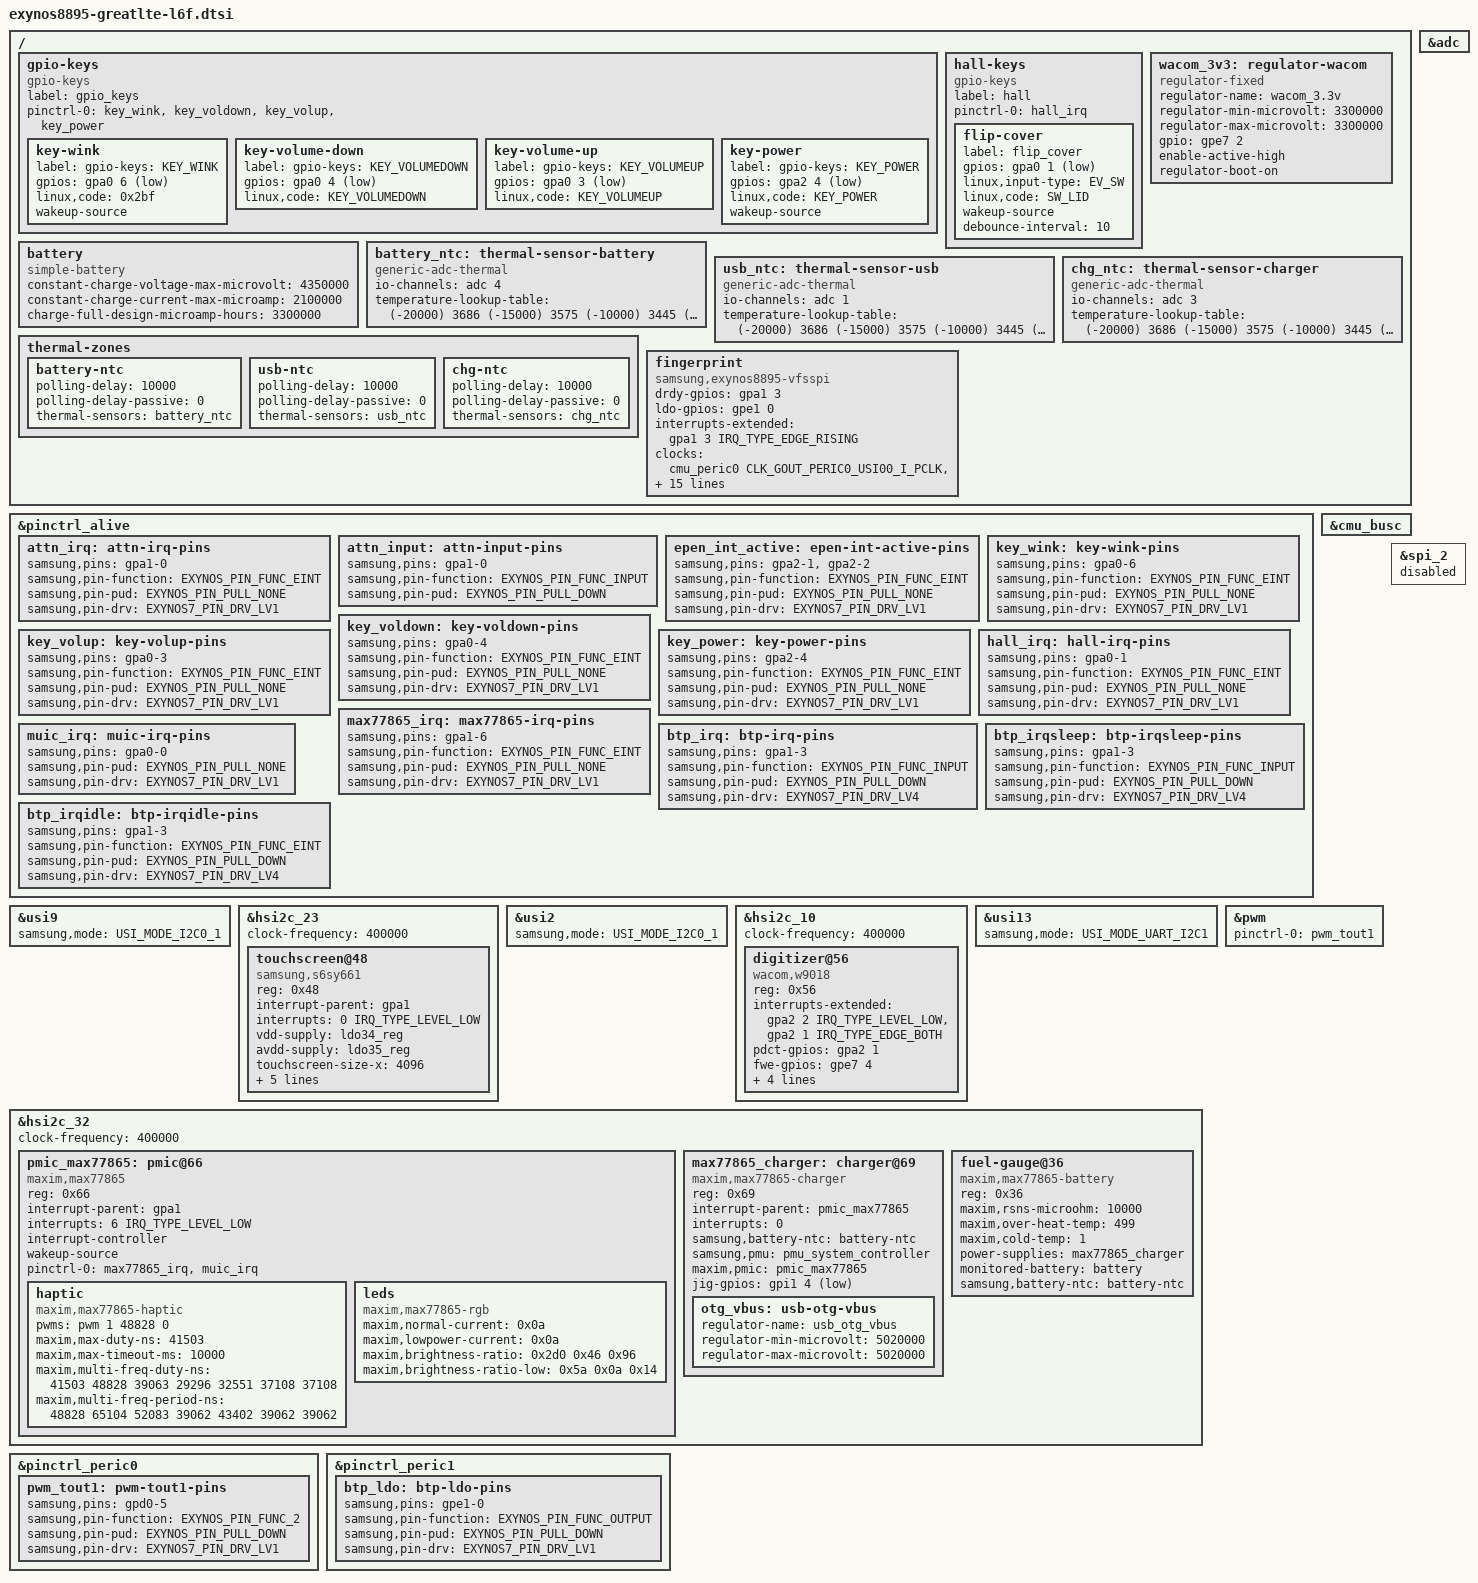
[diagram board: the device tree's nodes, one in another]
// SPDX-License-Identifier: GPL-2.0 OR BSD-3-Clause
/*
 * Samsung Galaxy Note 8 (greatlte, SM-N950N) board DT, part "l6f":
 * L6F power/input/misc: charger, fuel gauge, touch, S Pen, keys, fingerprint (L6F 4).
 *
 * Included at the end of exynos8895-greatlte.dts, after L0's nodes, in the merge
 * order of FULL_IMAGE_PLAN.md 2.2. Owner: WP-6F; no other work package edits this
 * file (plan 2.3 rule D1). A node that two parts both configure (&usi9, &usi10)
 * is written identically in both files: dtc lets the later file win on a differing
 * value, which gl-verify V-DUP reports as an error. L0's reserved-memory stays in
 * the .dts; carveout additions and flag changes are &label edits here (plan X-8).
 */
&pinctrl_alive {
	attn_irq: attn-irq-pins {			/* FDT:266-273 (0x66), touch on_state */
		samsung,pins = "gpa1-0";
		samsung,pin-function = <EXYNOS_PIN_FUNC_EINT>;
		samsung,pin-pud = <EXYNOS_PIN_PULL_NONE>;
		samsung,pin-drv = <EXYNOS7_PIN_DRV_LV1>;
	};
	attn_input: attn-input-pins {			/* FDT:275-281 (0x67), touch off_state; stock sets no drv */
		samsung,pins = "gpa1-0";
		samsung,pin-function = <EXYNOS_PIN_FUNC_INPUT>;
		samsung,pin-pud = <EXYNOS_PIN_PULL_DOWN>;	/* pud 1 */
	};
	/* greatlte L6F slice pen (L6F 4.2) */
	epen_int_active: epen-int-active-pins {		/* FDT:354-361 (0x4e) */
		samsung,pins = "gpa2-1", "gpa2-2";
		samsung,pin-function = <EXYNOS_PIN_FUNC_EINT>;
		samsung,pin-pud = <EXYNOS_PIN_PULL_NONE>;
		samsung,pin-drv = <EXYNOS7_PIN_DRV_LV1>;
	};
};

&usi9 {
	samsung,mode = <USI_MODE_I2C0_1>;		/* stock usi@1082101C "hsi2c0_hsi2c1" FDT:5049-5053 */
	status = "okay";
};

&hsi2c_23 {						/* stock hsi2c@108E0000 FDT:5666-5683 (SPI 0x19a = 410) */
	clock-frequency = <400000>;		/* no clock-frequency in FDT:5666-5683 -> stock 400 kHz default (as 4.3) */
	status = "okay";

	touchscreen@48 {
		compatible = "samsung,s6sy661";		/* new s6sy761 variant (5.12); stock "sec,sec_ts" FDT:5685 */
		reg = <0x48>;				/* FDT:5686 */
		interrupt-parent = <&gpa1>;
		interrupts = <0 IRQ_TYPE_LEVEL_LOW>;	/* FDT:5692 sec,irq_gpio = <&gpa1 0 0>; FDT:5693 irq_type 0x2008 =
							   IRQF_ONESHOT | IRQF_TRIGGER_LOW */
		vdd-supply = <&ldo34_reg>;		/* FDT:5696 "tsp_io" (L2_power.md:646-651) */
		avdd-supply = <&ldo35_reg>;		/* FDT:5697 "tsp_avdd" (L2_power.md:652-657) */
		touchscreen-size-x = <4096>;		/* FDT:5694 sec,max_coords 0xfff = size - 1; chip value - 1 in stock (sec_ts.c:1922-1926) */
		touchscreen-size-y = <4096>;
		pinctrl-names = "default", "sleep";	/* FDT:5687 "on_state", "off_state" */
		pinctrl-0 = <&attn_irq>;		/* FDT:5688 0x66 */
		pinctrl-1 = <&attn_input>;		/* FDT:5689 0x67 */
		samsung,sponge-model = "N950";		/* stock sec,project_name = "GREAT", "N950" (S:arch/arm64/boot/dts/exynos/
							   exynos8895-greatlte_common.dtsi:3256; model_name = entry 1, sec_ts.c:1801-1802)
							   and pressure-sensor = "Y" (:3245): the under-display pressure home key */
		panel = <&panel>;			/* run 7: DRM panel follower, 5.12 item 13 (closes O-TS3); label from
							   L5 (REQ-L5-1); delete to keep touch powered while awake */
	};
};

/* Keys and hall (L6F slice A) */
#include <dt-bindings/input/input.h>

&pinctrl_alive {
	key_wink: key-wink-pins {			/* FDT:283-290 (phandle 0x145) */
		samsung,pins = "gpa0-6";
		samsung,pin-function = <EXYNOS_PIN_FUNC_EINT>;	/* 0x0f */
		samsung,pin-pud = <EXYNOS_PIN_PULL_NONE>;
		samsung,pin-drv = <EXYNOS7_PIN_DRV_LV1>;
	};
	key_voldown: key-voldown-pins {			/* FDT:292-299 (0x146) */
		samsung,pins = "gpa0-4";
		samsung,pin-function = <EXYNOS_PIN_FUNC_EINT>;
		samsung,pin-pud = <EXYNOS_PIN_PULL_NONE>;
		samsung,pin-drv = <EXYNOS7_PIN_DRV_LV1>;
	};
	key_volup: key-volup-pins {			/* FDT:301-308 (0x147) */
		samsung,pins = "gpa0-3";
		samsung,pin-function = <EXYNOS_PIN_FUNC_EINT>;
		samsung,pin-pud = <EXYNOS_PIN_PULL_NONE>;
		samsung,pin-drv = <EXYNOS7_PIN_DRV_LV1>;
	};
	key_power: key-power-pins {			/* FDT:310-317 (0x148) */
		samsung,pins = "gpa2-4";
		samsung,pin-function = <EXYNOS_PIN_FUNC_EINT>;
		samsung,pin-pud = <EXYNOS_PIN_PULL_NONE>;
		samsung,pin-drv = <EXYNOS7_PIN_DRV_LV1>;
	};
	hall_irq: hall-irq-pins {			/* FDT:248-255 (0x142) */
		samsung,pins = "gpa0-1";
		samsung,pin-function = <EXYNOS_PIN_FUNC_EINT>;
		samsung,pin-pud = <EXYNOS_PIN_PULL_NONE>;
		samsung,pin-drv = <EXYNOS7_PIN_DRV_LV1>;
	};
};

/ {
	gpio-keys {
		compatible = "gpio-keys";			/* FDT:11246 */
		label = "gpio_keys";				/* input name = stock "gpio_keys" (recon/input/input.txt:57);
								   A:drivers/input/keyboard/gpio_keys.c:778, :879 */
		pinctrl-names = "default";
		pinctrl-0 = <&key_wink &key_voldown &key_volup &key_power>;	/* FDT:11250 <0x145..0x148> */

		key-wink {
			label = "gpio-keys: KEY_WINK";		/* FDT:11253 */
			gpios = <&gpa0 6 GPIO_ACTIVE_LOW>;	/* FDT:11257 <0x90 6 0xf> (bit 0 = active low) */
			linux,code = <0x2bf>;			/* FDT:11256; Samsung KEY_WINK S:include/uapi/linux/input-event-codes.h:341,
								   inside 6.18 KEY_MAX 0x2ff A:include/uapi/linux/input-event-codes.h:837 */
			wakeup-source;				/* FDT:11258 gpio-key,wakeup */
		};
		key-volume-down {
			label = "gpio-keys: KEY_VOLUMEDOWN";	/* FDT:11262 */
			gpios = <&gpa0 4 GPIO_ACTIVE_LOW>;	/* FDT:11266 */
			linux,code = <KEY_VOLUMEDOWN>;		/* 0x72 FDT:11265 */
		};
		key-volume-up {
			label = "gpio-keys: KEY_VOLUMEUP";	/* FDT:11270 */
			gpios = <&gpa0 3 GPIO_ACTIVE_LOW>;	/* FDT:11274 */
			linux,code = <KEY_VOLUMEUP>;		/* 0x73 FDT:11273 */
		};
		key-power {
			label = "gpio-keys: KEY_POWER";		/* FDT:11278 */
			gpios = <&gpa2 4 GPIO_ACTIVE_LOW>;	/* FDT:11282 <0x4f 4 0xf> (0x4f = gpa2) */
			linux,code = <KEY_POWER>;		/* 0x74 FDT:11281 */
			wakeup-source;				/* FDT:11283 */
		};
	};

	hall-keys {
		compatible = "gpio-keys";
		label = "hall";					/* stock input name S:drivers/input/hall.c:252 */
		pinctrl-names = "default";
		pinctrl-0 = <&hall_irq>;			/* FDT:11206 0x142 */

		flip-cover {
			label = "flip_cover";
			gpios = <&gpa0 1 GPIO_ACTIVE_LOW>;	/* FDT:11207 hall,gpio_flip_cover = <&gpa0 1 0>; level 1 = open
								   (S:drivers/input/hall.c:98-104), so active-low = closed */
			linux,input-type = <EV_SW>;
			linux,code = <SW_LID>;			/* 0x00 A:include/uapi/linux/input-event-codes.h:934; stock SW_FLIP 0x15 > SW_MAX 0x11 (:954) */
			wakeup-source;
			debounce-interval = <10>;		/* stock 10 ms on open, 0 on close: S:drivers/input/hall.c:115-121 */
		};
	};
};

/* greatlte L6F slice pen (L6F 4.9) */
/ {
	wacom_3v3: regulator-wacom {
		compatible = "regulator-fixed";			/* FDT:11963-11971 wacom_ldo_en */
		regulator-name = "wacom_3.3v";			/* FDT:11965 */
		regulator-min-microvolt = <3300000>;		/* FDT:11966 0x325aa0 */
		regulator-max-microvolt = <3300000>;
		gpio = <&gpe7 2 GPIO_ACTIVE_HIGH>;		/* FDT:11968 <0x51 2 0> (0x51 = gpe7) */
		enable-active-high;				/* FDT:11969 */
		regulator-boot-on;				/* FDT:11970 */
	};
};

&usi2 {
	samsung,mode = <USI_MODE_I2C0_1>;		/* stock usi@10421008 "hsi2c0_hsi2c1" FDT:5001-5005 */
	status = "okay";
};

&hsi2c_10 {						/* stock hsi2c@10490000 FDT:5350-5366 (SPI 0x175 = 373) */
	clock-frequency = <400000>;		/* no clock-frequency in FDT:5350-5366 -> stock 400 kHz default (as 4.3) */
	status = "okay";

	digitizer@56 {
		compatible = "wacom,w9018";		/* new driver (5.13); stock "wacom,w90xx" FDT:5369 */
		reg = <0x56>;				/* FDT:5370 */
		interrupts-extended = <&gpa2 2 IRQ_TYPE_LEVEL_LOW>,	/* data: FDT:5376 wacom,irq-gpio = <&gpa2 2 1>; FDT:5379 irq_type 0x08 =
								   IRQF_TRIGGER_LOW. Stock "interrupts = <3 0 0>" (FDT:5373) is unused: stock takes
								   the IRQ from the gpio (S:drivers/input/wacom/wacom_i2c.c:2848) */
				      <&gpa2 1 IRQ_TYPE_EDGE_BOTH>;	/* pdct: S:.../wacom_i2c.c:2849, :2961-2965 FALLING|RISING */
		interrupt-names = "data", "pdct";
		pdct-gpios = <&gpa2 1 GPIO_ACTIVE_HIGH>;	/* FDT:5377 wacom,pdct-gpio = <&gpa2 1 1>; stock ignores the flag and uses the raw
							   level, 1 = pen in the garage (S:drivers/input/wacom/wacom_i2c.c:1736-1750), so
							   active-high makes gpiod_get_value() = "inserted" (SW_PEN_INSERTED semantics) */
		fwe-gpios = <&gpe7 4 GPIO_ACTIVE_HIGH>;	/* FDT:5378 */
		vddo-supply = <&wacom_3v3>;		/* FDT:5375 */
		wacom,xy-switch;			/* FDT:5388 wacom,invert = <1 0 1>: x_invert 1, y_invert 0, xy_switch 1 */
		wacom,x-invert;
		pinctrl-names = "default";
		pinctrl-0 = <&epen_int_active>;		/* FDT:5372 0x4e */
	};
};

/* ---- slice pwr: MAX77865 MFD, charger, fuel gauge, battery, AP ADC + NTC (L6F 4.2-4.4) ---- */
#include <dt-bindings/gpio/gpio.h>

&pinctrl_alive {
	max77865_irq: max77865-irq-pins {		/* FDT:467-474 (0x8d) */
		samsung,pins = "gpa1-6";
		samsung,pin-function = <EXYNOS_PIN_FUNC_EINT>;	/* 0x0f */
		samsung,pin-pud = <EXYNOS_PIN_PULL_NONE>;
		samsung,pin-drv = <EXYNOS7_PIN_DRV_LV1>;
	};
	muic_irq: muic-irq-pins {			/* FDT:476-482 (0x8e): stock sets no function */
		samsung,pins = "gpa0-0";
		samsung,pin-pud = <EXYNOS_PIN_PULL_NONE>;
		samsung,pin-drv = <EXYNOS7_PIN_DRV_LV1>;
	};
};

/* the AP ADC's clock provider (L1b CMU_BUSC, REQ-L1-6; enabled with the ADC, commit d98884fd8) */
&cmu_busc {
	status = "okay";
};

&adc {
	status = "okay";
};

/* identical to exynos8895-greatlte-l3.dtsi (plan 2.3 D1) */
&usi13 {
	samsung,mode = <USI_MODE_UART_I2C1>;	/* stock usi@1082102C usi_mode = "uart_hsi2c1" FDT:5077-5081 */
	status = "okay";
};

&hsi2c_32 {					/* stock hsi2c@10970000 FDT:6149-6163 (SPI 0x1ab = 427) */
	#address-cells = <1>;			/* FDT:6154 (the ACK node has none) */
	#size-cells = <0>;			/* FDT:6155 */
	clock-frequency = <400000>;		/* FDT:6149-6163 has no clock-frequency -> stock default
						   HSI2C_FS_TX_CLOCK 400000 (S:drivers/i2c/busses/i2c-exynos5.c:212,1572-1574) */
	status = "okay";

	pmic_max77865: pmic@66 {
		compatible = "maxim,max77865";			/* FDT:6166 */
		reg = <0x66>;					/* FDT:6169 */
		interrupt-parent = <&gpa1>;
		interrupts = <6 IRQ_TYPE_LEVEL_LOW>;		/* FDT:6170 max77865,irq-gpio = <&gpa1 6 1>;
								   S:drivers/mfd/max77865-irq.c:286-287 IRQF_TRIGGER_LOW */
		interrupt-controller;				/* INTSRC demux (L6F 5.2) */
		#interrupt-cells = <1>;
		wakeup-source;					/* FDT:6173 max77865,wakeup */
		pinctrl-names = "default";
		pinctrl-0 = <&max77865_irq &muic_irq>;		/* FDT:6168 <0x8d 0x8e 0x8f>; 0x8f (pwm-tout1) is the PWM's */

		/* slice hlp: haptic and LED child nodes (L6F 4.3) */
		haptic {
			compatible = "maxim,max77865-haptic";
			pwms = <&pwm 1 48828 0>;		/* FDT:12440 haptic,pwm_id = <1>; FDT:12438 period[0] 0xbebc;
								   index 0 = default S:drivers/motor/max77865_haptic.c:726 */
			maxim,max-duty-ns = <41503>;		/* FDT:12437 haptic,duty[0] 0xa21f (5.7) */
			maxim,max-timeout-ms = <10000>;		/* FDT:12435 haptic,max_timeout = <0x2710> */
			/*
			 * Samsung's haptic,duty and haptic,period (exynos8895-greatlte_motor.dtsi):
			 * alert, low, mid, high, 0, home key press, home key release
			 */
			maxim,multi-freq-duty-ns = <41503 48828 39063 29296 32551 37108 37108>;
			maxim,multi-freq-period-ns = <48828 65104 52083 39062 43402 39062 39062>;
		};

		leds {
			compatible = "maxim,max77865-rgb";
			/* FDT:12444-12511: every window-colour variant (_uu _bk _wh _gd _sv _gr _bl _pg) carries the same values
			 * (python check of the rgb node), so no lcdtype lookup is needed */
			maxim,normal-current = <0x0a>;		/* normal_powermode_current_uu FDT:12447 */
			maxim,lowpower-current = <0x0a>;	/* low_powermode_current_uu FDT:12448 */
			maxim,brightness-ratio = <0x2d0 0x46 0x96>;	/* br_ratio_r/g/b_uu FDT:12449-12451 */
			maxim,brightness-ratio-low = <0x5a 0x0a 0x14>;	/* br_ratio_r/g/b_low_uu FDT:12452-12454 */
		};
	};

	max77865_charger: charger@69 {			/* 0xD2 >> 1: S:drivers/mfd/max77865.c:46 */
		compatible = "maxim,max77865-charger";
		reg = <0x69>;
		interrupt-parent = <&pmic_max77865>;
		interrupts = <0>;			/* INTSRC bit 0 CHG: S:include/linux/mfd/max77865-private.h:30 */
		samsung,battery-ntc = "battery-ntc";	/* thermal zone below (L6F 4.4) */
		samsung,pmu = <&pmu_system_controller>;	/* INFORM2 write on power-off with charger (L6F 5.3.7) */
		maxim,pmic = <&pmic_max77865>;		/* core regmap for MAINCTRL1 (L6F 5.3.2 step 12) */
		jig-gpios = <&gpi1 4 GPIO_ACTIVE_LOW>;	/* FDT:12332-12333 fuelgauge,jig_gpio = <&gpi1 4 0> + jig_low_active
						   (0x8a = gpi1, FDT:705-711); requested GPIOD_ASIS (V4-16) */
		/*
		 * samsung,charge-control; (L6F 4.3, 5.3.2) is left out for now: monitor-only until
		 * the readings are checked on the phone and the charge-control path is reviewed.
		 */

		otg_vbus: usb-otg-vbus {		/* stock "otg" supply as a regulator (L6F 5.3.8) */
			regulator-name = "usb_otg_vbus";
			regulator-min-microvolt = <5020000>;	/* CNFG_11 := 0x16 "Update CHG_CNFG_11 to 0x16(5.020V)"
								   S:drivers/battery_v2/max77865_charger.c:656-658 */
			regulator-max-microvolt = <5020000>;
			/* no consumer in this image (L3 peripheral-only); host-role owner: O-J21 */
		};
	};

	fuel-gauge@36 {					/* 0x6C >> 1: S:drivers/mfd/max77865.c:47 */
		compatible = "maxim,max77865-battery";
		reg = <0x36>;
		/* no interrupts: SALRT_Th := 0xff00 path (A:drivers/power/supply/max17042_battery.c:1117-1119) */
		maxim,rsns-microohm = <10000>;		/* FDT:12351 fuelgauge,fg_resistor = <1>;
							   S:drivers/battery_v2/max77865_fuelgauge.c:535-541 10 mOhm */
		maxim,over-heat-temp = <499>;		/* FDT:12225 temp_high_threshold_normal 0x1f4 (50.0 degC); stock
							   T >= 500 (S:drivers/battery_v2/sec_battery.c:1972), max17042
							   temp > temp_max (A:drivers/power/supply/max17042_battery.c:218) */
		maxim,cold-temp = <1>;			/* FDT:12227 temp_low_threshold_normal 0x00; stock T <= 0 (:2014),
							   max17042 temp < temp_min (:213) */
		/* no maxim,over-volt / maxim,dead-volt: stock has no battery-voltage health limit,
		 * battery,ovp_uvlo_check_type 3 = charger polling (FDT:12215, L6F 4.3, O-J15) */
		power-supplies = <&max77865_charger>;	/* STATUS needs a supplier (A:.../max17042_battery.c:119-127) */
		monitored-battery = <&battery>;
		samsung,battery-ntc = "battery-ntc";	/* host temperature source (L6F 5.4) */
	};
};

/ {
	battery: battery {
		compatible = "simple-battery";
		constant-charge-voltage-max-microvolt = <4350000>;	/* FDT:12281-12282 0xa9ec = 43500 / conv 0x0a */
		constant-charge-current-max-microamp = <2100000>;	/* FDT:12361 default_charging_current = <0x834> */
		charge-full-design-microamp-hours = <3300000>;		/* FDT:12312 battery,battery_full_capacity = <0xce4> */
	};

	/*
	 * Battery NTC = ADC 4, USB-connector NTC = ADC 1, charger NTC = ADC 3
	 * (FDT:12323-12324 "adc-temp" <0x141 0x04>, "adc-usb-temp" <0x141 0x01>,
	 * "adc-chg-temp" <0x141 0x03>). Tables: FDT:12188-12189 battery,temp_table_adc /
	 * temp_table_data as <milli-degC code> pairs, code falling, as
	 * gadc_thermal_adc_to_temp() needs (A:drivers/thermal/thermal-generic-adc.c:27-56);
	 * the usb and chg tables FDT:12190-12193 are equal to it.
	 */
	battery_ntc: thermal-sensor-battery {
		compatible = "generic-adc-thermal";		/* A:drivers/thermal/thermal-generic-adc.c:212-214 */
		#thermal-sensor-cells = <0>;
		io-channels = <&adc 4>;
		io-channel-names = "sensor-channel";
		temperature-lookup-table = <
			(-20000) 3686	(-15000) 3575	(-10000) 3445	(-5000) 3293
			0 3122		5000 2932	10000 2726	15000 2512
			20000 2291	25000 2048	30000 1811	35000 1586
			40000 1378	45000 1189	50000 1021	55000 887
			60000 769	65000 655	70000 558	75000 474
			80000 404	85000 345	90000 294 >;
	};

	usb_ntc: thermal-sensor-usb {
		compatible = "generic-adc-thermal";
		#thermal-sensor-cells = <0>;
		io-channels = <&adc 1>;
		io-channel-names = "sensor-channel";
		temperature-lookup-table = <
			(-20000) 3686	(-15000) 3575	(-10000) 3445	(-5000) 3293
			0 3122		5000 2932	10000 2726	15000 2512
			20000 2291	25000 2048	30000 1811	35000 1586
			40000 1378	45000 1189	50000 1021	55000 887
			60000 769	65000 655	70000 558	75000 474
			80000 404	85000 345	90000 294 >;
	};

	chg_ntc: thermal-sensor-charger {
		compatible = "generic-adc-thermal";
		#thermal-sensor-cells = <0>;
		io-channels = <&adc 3>;
		io-channel-names = "sensor-channel";
		temperature-lookup-table = <
			(-20000) 3686	(-15000) 3575	(-10000) 3445	(-5000) 3293
			0 3122		5000 2932	10000 2726	15000 2512
			20000 2291	25000 2048	30000 1811	35000 1586
			40000 1378	45000 1189	50000 1021	55000 887
			60000 769	65000 655	70000 558	75000 474
			80000 404	85000 345	90000 294 >;
	};

	thermal-zones {
		battery-ntc {
			polling-delay = <10000>;	/* 10 s = FDT:12187 battery,polling_time[0] (BASIC) 0x0a */
			polling-delay-passive = <0>;
			thermal-sensors = <&battery_ntc>;
			/* no trips: allowed (A:drivers/thermal/thermal_of.c:387-395) */
		};

		usb-ntc {
			polling-delay = <10000>;	/* same cadence as battery-ntc */
			polling-delay-passive = <0>;
			thermal-sensors = <&usb_ntc>;
		};

		chg-ntc {
			polling-delay = <10000>;
			polling-delay-passive = <0>;
			thermal-sensors = <&chg_ntc>;
		};
	};
};

/* slice hlp: PWM pin and board PWM (L6F 4.2, 4.5) */
&pinctrl_peric0 {
	pwm_tout1: pwm-tout1-pins {			/* FDT:1529-1535 (0x8f) */
		samsung,pins = "gpd0-5";
		samsung,pin-function = <EXYNOS_PIN_FUNC_2>;
		samsung,pin-pud = <EXYNOS_PIN_PULL_DOWN>;	/* pud 1 */
		samsung,pin-drv = <EXYNOS7_PIN_DRV_LV1>;
	};
};

&pwm {
	pinctrl-names = "default";
	pinctrl-0 = <&pwm_tout1>;			/* stock applied through the MFD node (FDT:6168 third entry 0x8f) */
	status = "okay";
};

/* slice fp: fingerprint sensor, non-secure side (L6F 4.2, 4.7) */
&pinctrl_alive {
	btp_irq: btp-irq-pins {				/* FDT:424-431 (0x9f) */
		samsung,pins = "gpa1-3";
		samsung,pin-function = <EXYNOS_PIN_FUNC_INPUT>;
		samsung,pin-pud = <EXYNOS_PIN_PULL_DOWN>;	/* pud 1 */
		samsung,pin-drv = <EXYNOS7_PIN_DRV_LV4>;	/* 3 */
	};
	btp_irqsleep: btp-irqsleep-pins {		/* FDT:433-440 (0xa1) */
		samsung,pins = "gpa1-3";
		samsung,pin-function = <EXYNOS_PIN_FUNC_INPUT>;
		samsung,pin-pud = <EXYNOS_PIN_PULL_DOWN>;
		samsung,pin-drv = <EXYNOS7_PIN_DRV_LV4>;
	};
	btp_irqidle: btp-irqidle-pins {			/* FDT:442-449 (0xa2) */
		samsung,pins = "gpa1-3";
		samsung,pin-function = <EXYNOS_PIN_FUNC_EINT>;
		samsung,pin-pud = <EXYNOS_PIN_PULL_DOWN>;
		samsung,pin-drv = <EXYNOS7_PIN_DRV_LV4>;
	};
};

&pinctrl_peric1 {
	btp_ldo: btp-ldo-pins {				/* FDT:3860-3867 (0xa0) */
		samsung,pins = "gpe1-0";
		samsung,pin-function = <EXYNOS_PIN_FUNC_OUTPUT>;
		samsung,pin-pud = <EXYNOS_PIN_PULL_DOWN>;
		samsung,pin-drv = <EXYNOS7_PIN_DRV_LV1>;
	};
};

&spi_2 { status = "disabled"; };	/* FDT:6282 secure-mode: TEE owns the controller; usi0 never programmed (REQ-L1-3b, plan X-16) */

/ {
	fingerprint {
		compatible = "samsung,exynos8895-vfsspi";	/* platform device, not an SPI child (L6F 5.10) */
		drdy-gpios = <&gpa1 3 GPIO_ACTIVE_HIGH>;	/* FDT:6294 vfsspi-drdyPin = <&gpa1 3 0> (0x69 = gpa1) */
		ldo-gpios = <&gpe1 0 GPIO_ACTIVE_HIGH>;		/* FDT:6295 vfsspi-ldoPin = <&gpe1 0 0> (0x5b = gpe1) */
		interrupts-extended = <&gpa1 3 IRQ_TYPE_EDGE_RISING>;	/* DRDY: S:drivers/fingerprint/vfs8xxx.h:26 DRDY_IRQ_FLAG IRQF_TRIGGER_RISING */
		clocks = <&cmu_peric0 CLK_GOUT_PERIC0_USI00_I_PCLK>,	/* stock "fp-spi-pclk" GATE_USI00 S:drivers/clk/samsung/clk-exynos8895.c:372 */
			 <&cmu_peric0 CLK_GOUT_PERIC0_USI00_I_SCLK_USI>,
			 <&cmu_top CLK_DOUT_CMU_PERIC0_USI00>,		/* stock "fp-spi-sclk" (:542), rate set 2 x 13 MHz (5.10) */
			 <&cmu_peric0 CLK_GOUT_PERIC0_USI00_QCH>;	/* REQ-L1-10: the Q-channel CLOCK_REQ gate stock drives for
									   GATE_USI00 (VCLK_QCH_DIS) */
		clock-names = "pclk", "sclk_gate", "sclk", "qch";
		/* stock fp-spi-sclk vclk at 26000 kHz = TOP mux USI00 := OSCCLK (0), div := /1 (V4-11:
		 * S:drivers/soc/samsung/cal-if/exynos8895/cmucal-vclk.c:2586-2593, cmucal-vclklut.c:158-160);
		 * ACK muxes never reparent on set_rate (A:drivers/clk/samsung/clk.h:144-145), so select the parent here */
		assigned-clocks = <&cmu_top CLK_MOUT_CMU_PERIC0_USI00>, <&cmu_top CLK_DOUT_CMU_PERIC0_USI00>;
		assigned-clock-parents = <&oscclk>, <0>;
		assigned-clock-rates = <0>, <26000000>;
		spi-max-frequency = <13000000>;			/* FDT:6287 0xc65d40; S:drivers/fingerprint/vfs8xxx.h:20 */
		samsung,orient = <1>;				/* FDT:6296 vfsspi-orient */
		samsung,detect-mode = <1>;			/* FDT:6297 vfsspi-wog (DETECT_ADM, S:drivers/fingerprint/fingerprint.h:49) */
		samsung,chip-id = "NAMSAN";			/* FDT:6298 vfsspi-chipid */
		pinctrl-names = "default", "sleep", "idle";	/* FDT:6288-6291 */
		pinctrl-0 = <&spi2_bus &btp_irq &btp_ldo>;	/* stock child <0x9f 0xa0> + controller's spi2-bus 0x9e (FDT:6280) */
		pinctrl-1 = <&btp_irqsleep>;			/* FDT:6290 0xa1 */
		pinctrl-2 = <&btp_irqidle>;			/* FDT:6291 0xa2 */
		/* no CS gpio: secure mode never requests vfsspi-csgpio (S:drivers/fingerprint/vfs8xxx.c:1298-1308, :1580-1606) */
	};
};
